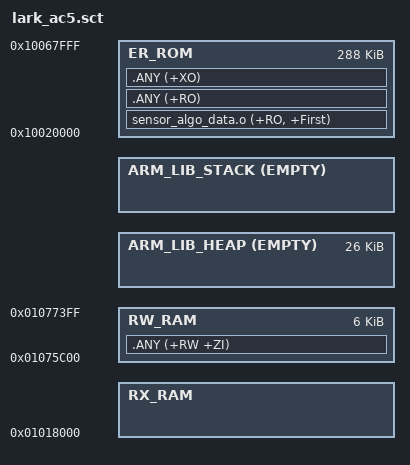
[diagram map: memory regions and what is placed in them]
#! armcc -E
; command above MUST be in first line (no comment above!)

/*
;-------- <<< Use Configuration Wizard in Context Menu >>> -------------------
*/

/*--------------------- Flash Configuration ----------------------------------
; <h> Flash Configuration
;   <o0> Flash Base Address <0x0-0xFFFFFFFF:8>
;   <o1> Flash Size (in Bytes) <0x0-0xFFFFFFFF:8>
; </h>
 *----------------------------------------------------------------------------*/
#define __ROM_BASE      0x10020000
#define __ROM_SIZE      0x00048000

/*--------------------- Embedded RAM Configuration ---------------------------
; <h> RAM Configuration
;   <o0> RAM Base Address    <0x0-0xFFFFFFFF:8>
;   <o1> RAM Size (in Bytes) <0x0-0xFFFFFFFF:8>
; </h>
 *----------------------------------------------------------------------------*/
#define __RAM_BASE      0x01075C00
#define __RAM_SIZE      0x00008000

/*--------------------- Embedded RAM Configuration ---------------------------
; <h> RAM Code Configuration
;   <o0> RAM Code Base Address    <0x0-0xFFFFFFFF:8>
;   <o1> RAM Code Size (in Bytes) <0x0-0xFFFFFFFF:8>
; </h>
 *----------------------------------------------------------------------------*/
#define __RAMX_SIZE      0x00000000
#define __RAMX_BASE      (0x01018000 - __RAMX_SIZE)

/*--------------------- Stack / Heap Configuration ---------------------------
; <h> Stack / Heap Configuration
;   <o0> Stack Size (in Bytes) <0x0-0xFFFFFFFF:8>
;   <o1> Heap Size (in Bytes) <0x0-0xFFFFFFFF:8>
; </h>
 *----------------------------------------------------------------------------*/
#define __STACK_SIZE    0x00000000
#define __HEAP_SIZE     0x00006800

/*
;------------- <<< end of configuration section >>> ---------------------------
*/


/*----------------------------------------------------------------------------
  User Stack & Heap boundary definition
 *----------------------------------------------------------------------------*/
#define __STACK_TOP    (__RAM_BASE + __RAM_SIZE)    /* starts at end of RAM */
#define __HEAP_BASE    (AlignExpr(+0, 8))           /* starts after RW_RAM section, 8 byte aligned */


/*----------------------------------------------------------------------------
  Scatter File Definitions definition
 *----------------------------------------------------------------------------*/
#define __RO_BASE       __ROM_BASE
#define __RO_SIZE       __ROM_SIZE

#define __RW_BASE       __RAM_BASE
#define __RW_SIZE      (__RAM_SIZE - __STACK_SIZE - __HEAP_SIZE)

#define __RX_BASE       __RAMX_BASE
#define __RX_SIZE       __RAMX_SIZE

LR_ROM __RO_BASE __RO_SIZE  {            ; load region size_region
  ER_ROM __RO_BASE __RO_SIZE  {                     ; load address = execution address
   sensor_algo_data.o (+RO, +First)
   .ANY (+RO)
   .ANY (+XO)
  }

  RX_RAM __RX_BASE __RX_SIZE  {                     ; RX data
#if __RX_SIZE > 0
   * (.cwm_sec.common_aml.p0)
   * (.cwm_sec.common_amh_proc.p3)
   cwm_watch_handupdown.o (+RO)
#endif
  }

  RW_RAM __RW_BASE __RW_SIZE  {                     ; RW data
   .ANY (+RW +ZI)
  }

#if __HEAP_SIZE > 0
  ARM_LIB_HEAP  __HEAP_BASE EMPTY  __HEAP_SIZE  {   ; Reserve empty region for heap
  }
#endif

  ARM_LIB_STACK __STACK_TOP EMPTY -__STACK_SIZE {   ; Reserve empty region for stack
  }
}
